# STC32G144K246 register map
Vendor: STC; File version: 2.0
Registers are 8-bit, read-write, no defined reset value unless marked. A register's access mark holds for its fields unless they carry their own. Offsets are from the block's base; [hi:lo] are bit positions; {n}, {i} and the like mark numbered series.

## GPIOB — PB 端口、模式、上下拉和中断
Base 0x007EF703
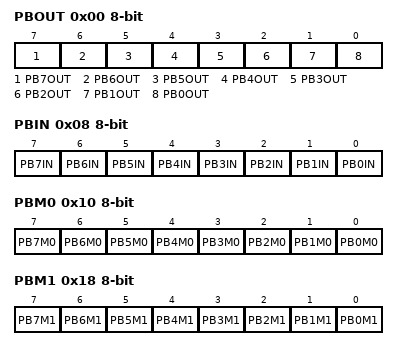
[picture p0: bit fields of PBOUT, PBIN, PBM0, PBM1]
0x00 PBOUT — PB端口输出寄存器
  [all] fields
    0=低电平; 1=高电平
  [7] PB7OUT — 设置 PB.7 的输出缓冲区电平。实际输出行为由端口模式及外设复用共同决定。
  [6] PB6OUT — 设置 PB.6 的输出缓冲区电平。实际输出行为由端口模式及外设复用共同决定。
  [5] PB5OUT — 设置 PB.5 的输出缓冲区电平。实际输出行为由端口模式及外设复用共同决定。
  [4] PB4OUT — 设置 PB.4 的输出缓冲区电平。实际输出行为由端口模式及外设复用共同决定。
  [3] PB3OUT — 设置 PB.3 的输出缓冲区电平。实际输出行为由端口模式及外设复用共同决定。
  [2] PB2OUT — 设置 PB.2 的输出缓冲区电平。实际输出行为由端口模式及外设复用共同决定。
  [1] PB1OUT — 设置 PB.1 的输出缓冲区电平。实际输出行为由端口模式及外设复用共同决定。
  [0] PB0OUT — 设置 PB.0 的输出缓冲区电平。实际输出行为由端口模式及外设复用共同决定。
0x08 PBIN ro — PB端口输入寄存器
  [all] fields
    0=低电平; 1=高电平
  [7] PB7IN — 读取 PB.7 管脚上的实际电平。
  [6] PB6IN — 读取 PB.6 管脚上的实际电平。
  [5] PB5IN — 读取 PB.5 管脚上的实际电平。
  [4] PB4IN — 读取 PB.4 管脚上的实际电平。
  [3] PB3IN — 读取 PB.3 管脚上的实际电平。
  [2] PB2IN — 读取 PB.2 管脚上的实际电平。
  [1] PB1IN — 读取 PB.1 管脚上的实际电平。
  [0] PB0IN — 读取 PB.0 管脚上的实际电平。
0x10 PBM0 — PB端口配置寄存器0
  [7] PB7M0 — 控制 PB.7 的端口模式低位；与 PBM1.B7 配合设置，组合含义见下表。
  [6] PB6M0 — 控制 PB.6 的端口模式低位；与 PBM1.B6 配合设置，组合含义见下表。
  [5] PB5M0 — 控制 PB.5 的端口模式低位；与 PBM1.B5 配合设置，组合含义见下表。
  [4] PB4M0 — 控制 PB.4 的端口模式低位；与 PBM1.B4 配合设置，组合含义见下表。
  [3] PB3M0 — 控制 PB.3 的端口模式低位；与 PBM1.B3 配合设置，组合含义见下表。
  [2] PB2M0 — 控制 PB.2 的端口模式低位；与 PBM1.B2 配合设置，组合含义见下表。
  [1] PB1M0 — 控制 PB.1 的端口模式低位；与 PBM1.B1 配合设置，组合含义见下表。
  [0] PB0M0 — 控制 PB.0 的端口模式低位；与 PBM1.B0 配合设置，组合含义见下表。
0x18 PBM1 — PB端口配置寄存器1
  [7] PB7M1 — 控制 PB.7 的端口模式高位；与 PBM0.B7 配合设置，组合含义见下表。
  [6] PB6M1 — 控制 PB.6 的端口模式高位；与 PBM0.B6 配合设置，组合含义见下表。
  [5] PB5M1 — 控制 PB.5 的端口模式高位；与 PBM0.B5 配合设置，组合含义见下表。
  [4] PB4M1 — 控制 PB.4 的端口模式高位；与 PBM0.B4 配合设置，组合含义见下表。
  [3] PB3M1 — 控制 PB.3 的端口模式高位；与 PBM0.B3 配合设置，组合含义见下表。
  [2] PB2M1 — 控制 PB.2 的端口模式高位；与 PBM0.B2 配合设置，组合含义见下表。
  [1] PB1M1 — 控制 PB.1 的端口模式高位；与 PBM0.B1 配合设置，组合含义见下表。
  [0] PB0M1 — 控制 PB.0 的端口模式高位；与 PBM0.B0 配合设置，组合含义见下表。
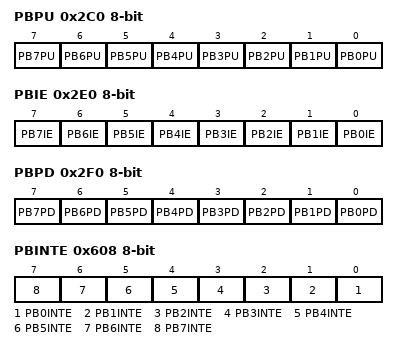
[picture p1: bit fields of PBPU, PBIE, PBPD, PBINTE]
0x2C0 PBPU — PB口上拉电阻控制寄存器
  [all] fields
    0=禁止内部上拉电阻; 1=使能内部上拉电阻
  [7] PB7PU — 控制 PB.7 的内部上拉电阻。
  [6] PB6PU — 控制 PB.6 的内部上拉电阻。
  [5] PB5PU — 控制 PB.5 的内部上拉电阻。
  [4] PB4PU — 控制 PB.4 的内部上拉电阻。
  [3] PB3PU — 控制 PB.3 的内部上拉电阻。
  [2] PB2PU — 控制 PB.2 的内部上拉电阻。
  [1] PB1PU — 控制 PB.1 的内部上拉电阻。
  [0] PB0PU — 控制 PB.0 的内部上拉电阻。
0x2E0 PBIE — PB口输入使能控制寄存器
  [all] fields
    0=禁止数字信号输入，用于模拟功能; 1=使能数字信号输入
  [7] PB7IE — 控制 PB.7 的数字信号输入。
  [6] PB6IE — 控制 PB.6 的数字信号输入。
  [5] PB5IE — 控制 PB.5 的数字信号输入。
  [4] PB4IE — 控制 PB.4 的数字信号输入。
  [3] PB3IE — 控制 PB.3 的数字信号输入。
  [2] PB2IE — 控制 PB.2 的数字信号输入。
  [1] PB1IE — 控制 PB.1 的数字信号输入。
  [0] PB0IE — 控制 PB.0 的数字信号输入。
0x2F0 PBPD — PB口下拉电阻控制寄存器
  [all] fields
    0=禁止内部下拉电阻; 1=使能内部下拉电阻
  [7] PB7PD — 控制 PB.7 的内部下拉电阻。
  [6] PB6PD — 控制 PB.6 的内部下拉电阻。
  [5] PB5PD — 控制 PB.5 的内部下拉电阻。
  [4] PB4PD — 控制 PB.4 的内部下拉电阻。
  [3] PB3PD — 控制 PB.3 的内部下拉电阻。
  [2] PB2PD — 控制 PB.2 的内部下拉电阻。
  [1] PB1PD — 控制 PB.1 的内部下拉电阻。
  [0] PB0PD — 控制 PB.0 的内部下拉电阻。
0x608 PBINTE — PB口中断使能寄存器
  [n] PB{n}INTE (n=0..7) — 尚未自动匹配到此字段的独立说明；请查看下方章节说明。
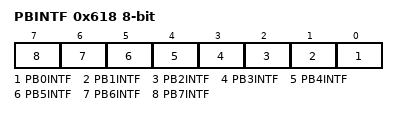
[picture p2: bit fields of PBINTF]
0x618 PBINTF ro — PB口中断标志寄存器
  [n] PB{n}INTF (n=0..7) — 尚未自动匹配到此字段的独立说明；请查看下方章节说明。

## GPIOInterrupts — GPIO 中断组优先级
Base 0x007EFD60
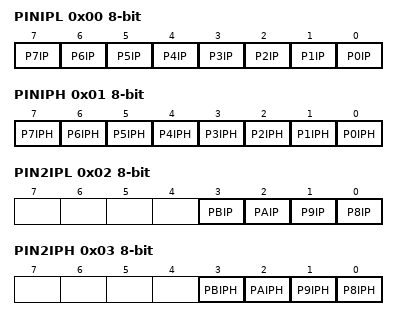
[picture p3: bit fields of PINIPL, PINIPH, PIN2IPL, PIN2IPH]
0x00 PINIPL — I/O口中断优先级低寄存器
  [n] P{n}IP (n=0..7) — 尚未自动匹配到此字段的独立说明；请查看下方章节说明。
0x01 PINIPH — I/O口中断优先级高寄存器
  [n] P{n}IPH (n=0..7) — 尚未自动匹配到此字段的独立说明；请查看下方章节说明。
0x02 PIN2IPL — I/O口中断优先级低寄存器2
  [3] PBIP — 尚未自动匹配到此字段的独立说明；请查看下方章节说明。
  [2] PAIP — 尚未自动匹配到此字段的独立说明；请查看下方章节说明。
  [1] P9IP — 尚未自动匹配到此字段的独立说明；请查看下方章节说明。
  [0] P8IP — 尚未自动匹配到此字段的独立说明；请查看下方章节说明。
0x03 PIN2IPH — I/O口中断优先级高寄存器2
  [3] PBIPH — 尚未自动匹配到此字段的独立说明；请查看下方章节说明。
  [2] PAIPH — 尚未自动匹配到此字段的独立说明；请查看下方章节说明。
  [1] P9IPH — 尚未自动匹配到此字段的独立说明；请查看下方章节说明。
  [0] P8IPH — 尚未自动匹配到此字段的独立说明；请查看下方章节说明。

## Timer0_1 — Timer0/1：共用控制、独立计数和预分频
Base 0x007EFEA0
0x00 TM0PS — 定时器0时钟预分频寄存器
  [7:0] TM0PS — 尚未自动匹配到此字段的独立说明；请查看下方章节说明。
0x01 TM1PS — 定时器1时钟预分频寄存器
  [7:0] TM1PS — 尚未自动匹配到此字段的独立说明；请查看下方章节说明。
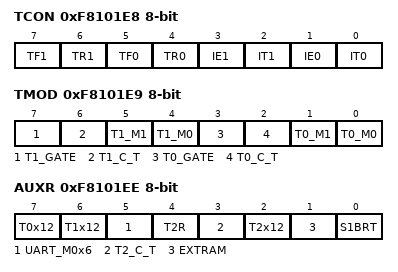
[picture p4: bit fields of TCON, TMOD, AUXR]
0xF8101E8 TCON — 定时器控制寄存器
  [7] TF1 — 定时器1溢出中断标志。中断服务程序中，硬件自动清零。
  [6] TR1 — 定时器T1的运行控制位。该位由软件置位和清零。当GATE（TMOD.7）=0，TR1=1时就允许T1
  [5] TF0 — 定时器0溢出中断标志。中断服务程序中，硬件自动清零。
  [4] TR0 — 定时器T0的运行控制位。该位由软件置位和清零。当GATE（TMOD.3）=0，TR0=1时就允许T0
  [3] IE1 — 外部中断1中断请求标志。中断服务程序中，硬件自动清零。
  [2] IT1 — INT1中断模式控制
    0=上升沿中断+下降沿中断; 1=下降沿中断
  [1] IE0 — 外部中断0中断请求标志。中断服务程序中，硬件自动清零。
  [0] IT0 — INT0中断模式控制
    0=上升沿中断+下降沿中断; 1=下降沿中断
0xF8101E9 TMOD — 定时器模式寄存器
  [7] T1_GATE — 控制定时器1，置1时只有在INT1脚为高及TR1控制位置1时才可打开定时器/计数器1。
  [6] T1_C_T — 控制定时器1用作定时器或计数器，清0则用作定时器（对内部系统时钟进行计数），置1用作
  [5] T1_M1 — 尚未自动匹配到此字段的独立说明；请查看下方章节说明。
  [4] T1_M0 — 尚未自动匹配到此字段的独立说明；请查看下方章节说明。
  [3] T0_GATE — 控制定时器0，置1时只有在INT0脚为高及TR0控制位置1时才可打开定时器/计数器0。
  [2] T0_C_T — 控制定时器0用作定时器或计数器，清0则用作定时器（对内部系统时钟进行计数），置1用作
  [1] T0_M1 — 尚未自动匹配到此字段的独立说明；请查看下方章节说明。
  [0] T0_M0 — 尚未自动匹配到此字段的独立说明；请查看下方章节说明。
0xF8101EA TL0 ro — 定时器0低8位寄存器
  [7:0] TMR0 — 尚未自动匹配到此字段的独立说明；请查看下方章节说明。
0xF8101EB TL1 ro — 定时器1低8位寄存器
  [7:0] TMR1 — 尚未自动匹配到此字段的独立说明；请查看下方章节说明。
0xF8101EC TH0 ro — 定时器0高8位寄存器
  [7:0] TMR0 — 尚未自动匹配到此字段的独立说明；请查看下方章节说明。
0xF8101ED TH1 ro — 定时器1高8位寄存器
  [7:0] TMR1 — 尚未自动匹配到此字段的独立说明；请查看下方章节说明。
0xF8101EE AUXR — 辅助寄存器1
  [7] T0x12 — 定时器0速度控制位
    0=12T 模式，即CPU 时钟12 分频（FOSC/12）; 1=1T 模式，即CPU 时钟不分频分频（FOSC/1）
  [6] T1x12 — 定时器1速度控制位
    0=12T 模式，即CPU 时钟12 分频（FOSC/12）; 1=1T 模式，即CPU 时钟不分频分频（FOSC/1）
  [5] UART_M0x6 — 串口1 模式0 的通讯速度控制
    0=串口1 模式0 的波特率不加倍，固定为Fosc/12; 1=串口1 模式0 的波特率6 倍速，即固定为Fosc/12*6 ＝ Fosc/2
  [4] T2R — 定时器2的运行控制位
    0=定时器2 停止计数; 1=定时器2 开始计数
  [3] T2_C_T — 控制定时器2用作定时器或计数器，清0则用作定时器（对内部系统时钟进行计数），置1用作
  [2] T2x12 — 定时器2速度控制位
    0=12T 模式，即CPU 时钟12 分频（FOSC/12）; 1=1T 模式，即CPU 时钟不分频分频（FOSC/1）
  [1] EXTRAM — 片外用户实际扩展的XRAM 访问控制
    0=可以访问内部扩展的XRAM，不能访问用户实际在外部用并行总线扩展的XRAM 或外设，这部分用; 1=禁止访问内部扩展的XRAM，可以访问用户实际在外部用并行总线扩展的XRAM 或外设，这部分用
  [0] S1BRT — 串口1 波特率发生器选择位
    0=选择定时器1 作为波特率发生器; 1=选择定时器2 作为波特率发生器（默认值）
